# ESP32S31_RADIO register map
Vendor: Espressif; Series: ESP32-S31; File version: 3.52
Registers are 32-bit, read-write, no defined reset value unless marked. A register's access mark holds for its fields unless they carry their own. Offsets are from the block's base; [hi:lo] are bit positions; {n}, {i} and the like mark numbered series.

## BT_V3_2_BASEBAND — Bluetooth baseband control and status words recovered from complete, named bt_bb_v2.o accessors in the ESP32-S31 vendor library. Field geometry and argument-to-field transforms are exact. ARGUMENT_N labels deliberately retain unknown C signature semantics rather than inventing a hardware meaning.
Base 0x20102000
0x00 RX_SETUP_CONTROL_0 — Complete bt_bb_rx_set sets positional bit 0 through a fresh-read RMW. Its independent hardware meaning remains unknown.
  [0] SET_BY_RX_SETUP_BIT_0 — Complete bt_bb_rx_set sets this positional bit. No enable semantic is proven.
0x04 CHANNEL_POWER_CONTROL — The named channel-power set/unset leaves set or clear this aggregate two-bit field through fresh-read RMW operations; individual bit meanings remain unknown.
  [9:8] CHANNEL_POWER_BITS_8_9 — bt_get_channel_pwr_set replaces the field with 3 and bt_get_channel_pwr_unset replaces it with 0.
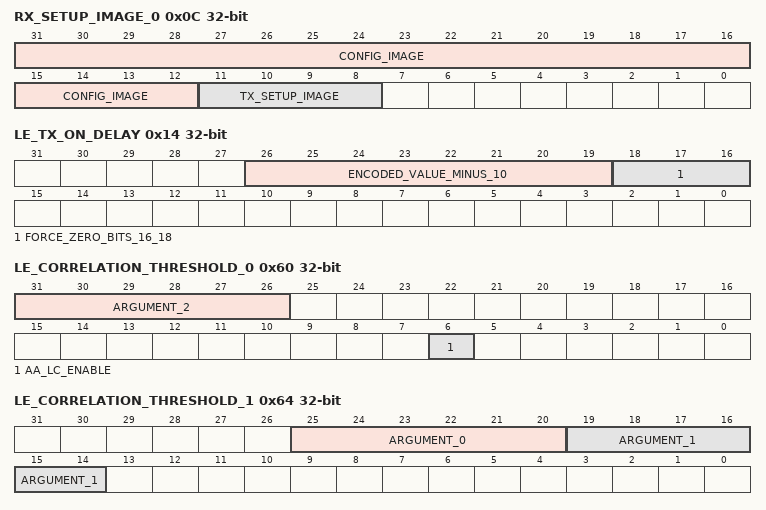
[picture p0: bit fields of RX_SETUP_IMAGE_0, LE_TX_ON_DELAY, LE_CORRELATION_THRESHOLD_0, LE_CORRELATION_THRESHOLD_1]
0x0C RX_SETUP_IMAGE_0 — The bounded TX setup clears bits 8:11; the subsequent RX setup preserves the low 12 bits and replaces bits 31:12 with the finite image 0x0199A.
  [31:12] CONFIG_IMAGE
  [11:8] TX_SETUP_IMAGE — bt_bb_v2_tx_set replaces this positional field with zero.
0x14 LE_TX_ON_DELAY — Bluetooth LE transmit-on delay. The public API exposes the decoded value; the register stores value minus 10.
  [26:19] ENCODED_VALUE_MINUS_10 — bt_bb_set_le_tx_on_delay stores argument 0 minus 10; bt_bb_get_le_tx_on_delay returns this field plus 10.
  [18:16] FORCE_ZERO_BITS_16_18 — bt_bb_set_le_tx_on_delay clears these three low positional bits in the same RMW that writes the encoded delay. Their hardware meaning remains unknown.
0x1C TX_CONFIG_CHECK_VALUE ro — ble_tx_config_check consumes only this high five-bit image in diagnostic arithmetic; its underlying hardware meaning remains unknown.
  [31:27] HIGH_5_UNKNOWN — Exact value produced by shifting the complete register image right by 27.
0x4C RX_SETUP_CONTROL_1 — Complete bt_bb_rx_set sets positional bit 2 through a fresh-read RMW. Its independent hardware meaning remains unknown.
  [2] SET_BY_RX_SETUP_BIT_2 — Complete bt_bb_rx_set sets this positional bit. No enable semantic is proven.
0x60 LE_CORRELATION_THRESHOLD_0 — Bluetooth LE correlation-threshold control. Only independently observed fields are assigned.
  [31:26] ARGUMENT_2 — bt_bb_set_corr_thresh_le copies its six-bit argument 2 image into this field.
  [6] AA_LC_ENABLE — bt_bb_corr_thresh_aa_lc_en replaces this bit with the Boolean image of argument 0.
0x64 LE_CORRELATION_THRESHOLD_1 — Two independently replaced six-bit Bluetooth LE correlation-threshold images.
  [25:20] ARGUMENT_0 — bt_bb_set_corr_thresh_le copies its six-bit argument 0 image into this field.
  [19:14] ARGUMENT_1 — bt_bb_set_corr_thresh_le copies its six-bit argument 1 image into this field.
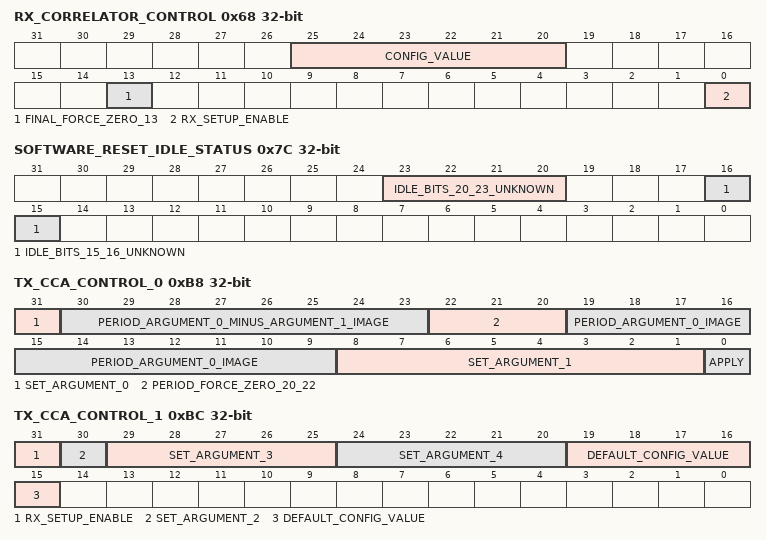
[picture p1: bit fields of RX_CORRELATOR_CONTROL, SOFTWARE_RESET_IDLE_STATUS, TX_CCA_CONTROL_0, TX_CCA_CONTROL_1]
0x68 RX_CORRELATOR_CONTROL — Bluetooth receive-correlator control. The finite initializer sets a low control bit and later replaces the independently observed six-bit configuration value.
  [25:20] CONFIG_VALUE — bt_bb_rx_correlator_set replaces this field with the finite value 8.
  [13] FINAL_FORCE_ZERO_13 — bt_bb_v2_rx_set clears this independently observed control bit after the receive leaf sequence.
  [0] RX_SETUP_ENABLE — bt_agc_restart_set sets this independently observed low control bit.
0x7C SOFTWARE_RESET_IDLE_STATUS ro — bbmac_idle_for_swrst requires both independently tested status fields to be zero before reporting idle.
  [23:20] IDLE_BITS_20_23_UNKNOWN — The reset-idle predicate fails when this exact four-bit field is nonzero.
  [16:15] IDLE_BITS_15_16_UNKNOWN — The reset-idle predicate fails when this exact two-bit field is nonzero.
0xB0 CURRENT_RX_INFO ro — Complete current Bluetooth receive-information image returned by bt_bb_get_cur_rx_info. Inner status encoding remains unknown.
  [31:0] IMAGE
0xB8 TX_CCA_CONTROL_0 — First Bluetooth transmit-CCA control word, including the period transform and fields supplied by bt_bb_tx_cca_set.
  [31] SET_ARGUMENT_0 — Boolean image of bt_bb_tx_cca_set argument 0.
  [30:23] PERIOD_ARGUMENT_0_MINUS_ARGUMENT_1_IMAGE — Eight-bit image produced by bt_bb_tx_cca_period from arguments 0 and 1 using the exact vendor arithmetic.
  [22:20] PERIOD_FORCE_ZERO_20_22 — bt_bb_tx_cca_period explicitly clears bits 20:22 in the same fresh-read update that replaces bits 23:30.
  [19:9] PERIOD_ARGUMENT_0_IMAGE — Eleven-bit image produced by bt_bb_tx_cca_period from argument 0 using the exact vendor arithmetic.
  [8:1] SET_ARGUMENT_1 — Eight-bit image of bt_bb_tx_cca_set argument 1.
  [0] APPLY — bt_bb_tx_cca_set unconditionally sets this bit after updating argument fields. No wider trigger semantics are claimed.
0xBC TX_CCA_CONTROL_1 — Second Bluetooth transmit-CCA control word. Argument meaning is not available from the stripped C signature.
  [31] RX_SETUP_ENABLE — bt_bb_rx_set sets this independently observed bit.
  [30] SET_ARGUMENT_2
  [29:25] SET_ARGUMENT_3
  [24:20] SET_ARGUMENT_4
  [19:15] DEFAULT_CONFIG_VALUE — bt_bb_cca_config replaces this field with the finite value 5.
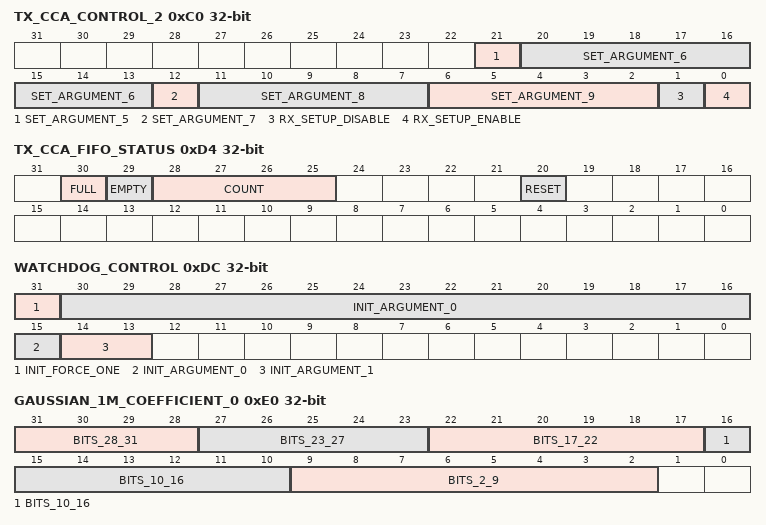
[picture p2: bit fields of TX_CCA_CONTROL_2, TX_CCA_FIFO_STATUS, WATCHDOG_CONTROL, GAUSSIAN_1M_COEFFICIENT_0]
0xC0 TX_CCA_CONTROL_2 — Third Bluetooth transmit-CCA control word. Argument meaning is not available from the stripped C signature.
  [21] SET_ARGUMENT_5
  [20:13] SET_ARGUMENT_6
  [12] SET_ARGUMENT_7
  [11:7] SET_ARGUMENT_8
  [6:2] SET_ARGUMENT_9
  [1] RX_SETUP_DISABLE — bt_bb_rx_set clears this bit before setting RX_SETUP_ENABLE.
  [0] RX_SETUP_ENABLE — bt_bb_rx_set sets this bit after clearing RX_SETUP_DISABLE.
0xD4 TX_CCA_FIFO_STATUS — Bluetooth transmit-CCA FIFO reset and status word recovered from five dedicated accessors.
  [30] FULL ro — Boolean returned by bt_bb_tx_cca_fifo_full.
  [29] EMPTY ro — Boolean returned by bt_bb_tx_cca_fifo_empty.
  [28:25] COUNT ro — Four-bit value returned by bt_bb_tx_cca_fifo_count.
  [20] RESET — bt_bb_tx_cca_fifo_reset sets this bit.
0xD8 TX_CCA_FIFO_DATA ro — Complete 32-bit FIFO word returned by bt_bb_tx_cca_fifo_read; inner encoding remains unknown.
  [31:0] IMAGE
0xDC WATCHDOG_CONTROL — Bluetooth baseband watchdog initialization word. Only the exact bt_bb_wdt_init writes are assigned.
  [31] INIT_FORCE_ONE — bt_bb_wdt_init sets this bit before writing both argument fields.
  [30:15] INIT_ARGUMENT_0 — Sixteen-bit image of bt_bb_wdt_init argument 0.
  [14:13] INIT_ARGUMENT_1 — Two-bit image of bt_bb_wdt_init argument 1.
0xE0 GAUSSIAN_1M_COEFFICIENT_0 — First word configured by the complete set_gauss_coeff_1m leaf; names retain positional fields because individual coefficient semantics are unknown.
  [31:28] BITS_28_31 — The leaf replaces this field with 0.
  [27:23] BITS_23_27 — The leaf replaces this field with 0.
  [22:17] BITS_17_22 — The leaf replaces this field with 0.
  [16:10] BITS_10_16 — The leaf replaces this field with 3.
  [9:2] BITS_2_9 — The leaf replaces this field with 0x13.
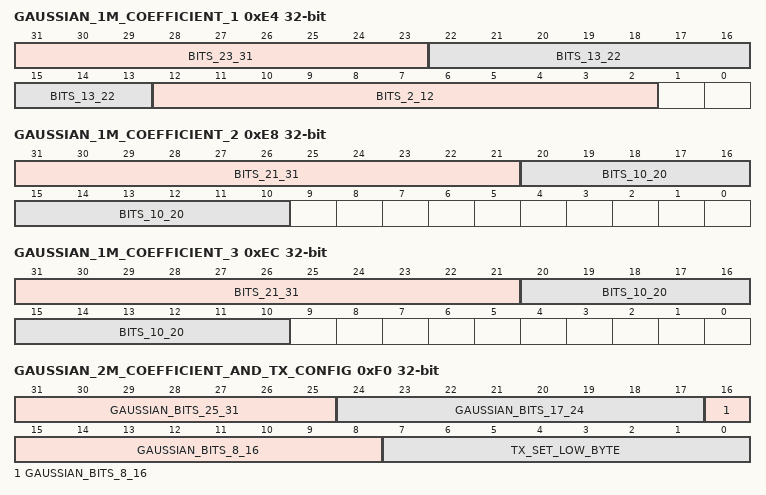
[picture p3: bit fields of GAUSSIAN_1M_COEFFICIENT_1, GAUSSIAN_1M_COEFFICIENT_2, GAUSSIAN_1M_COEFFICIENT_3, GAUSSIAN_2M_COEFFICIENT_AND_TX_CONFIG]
0xE4 GAUSSIAN_1M_COEFFICIENT_1 — Second word configured by the complete set_gauss_coeff_1m leaf.
  [31:23] BITS_23_31 — The leaf replaces this field with 0x5f.
  [22:13] BITS_13_22 — The leaf replaces this field with 0x140.
  [12:2] BITS_2_12 — The leaf replaces this field with 0x2f2.
0xE8 GAUSSIAN_1M_COEFFICIENT_2 — Third word configured by the complete set_gauss_coeff_1m leaf.
  [31:21] BITS_21_31 — The leaf replaces this field with 0x50d.
  [20:10] BITS_10_20 — The leaf replaces this field with 0x6bf.
0xEC GAUSSIAN_1M_COEFFICIENT_3 — Fourth word configured by the complete set_gauss_coeff_1m leaf.
  [31:21] BITS_21_31 — The leaf replaces this field with 0x7a0.
  [20:10] BITS_10_20 — The leaf replaces this field with 0x7e9.
0xF0 GAUSSIAN_2M_COEFFICIENT_AND_TX_CONFIG — The complete 2M Gaussian-coefficient leaf owns bits 31:8 while bt_bb_v2_tx_set independently owns the low-byte image of this same physical word.
  [31:25] GAUSSIAN_BITS_25_31 — set_gauss_coeff_2m replaces this field with 0.
  [24:17] GAUSSIAN_BITS_17_24 — set_gauss_coeff_2m replaces this field with 7.
  [16:8] GAUSSIAN_BITS_8_16 — set_gauss_coeff_2m replaces this field with 0x69.
  [7:0] TX_SET_LOW_BYTE — bt_bb_v2_tx_set replaces this field with 0xf5.
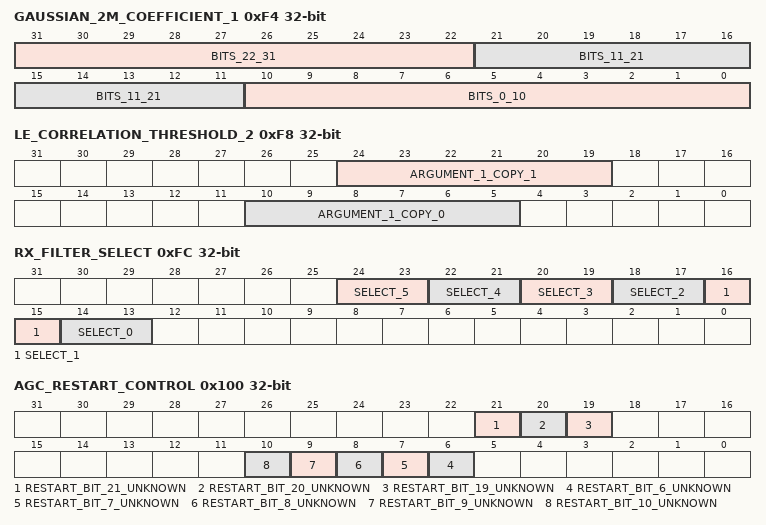
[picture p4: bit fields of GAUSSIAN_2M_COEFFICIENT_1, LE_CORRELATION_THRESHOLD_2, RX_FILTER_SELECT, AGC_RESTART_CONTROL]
0xF4 GAUSSIAN_2M_COEFFICIENT_1 — Second word configured by the complete set_gauss_coeff_2m leaf; its three observed fields cover the complete physical word.
  [31:22] BITS_22_31 — The leaf replaces this field with 0x258.
  [21:11] BITS_11_21 — The leaf replaces this field with 0x5a7.
  [10:0] BITS_0_10 — The leaf replaces this field with 0x78f.
0xF8 LE_CORRELATION_THRESHOLD_2 — Two copies of bt_bb_set_corr_thresh_le argument 1 in independently replaced six-bit fields.
  [24:19] ARGUMENT_1_COPY_1, [10:5] ARGUMENT_1_COPY_0
0xFC RX_FILTER_SELECT — Six independent two-bit Bluetooth receive-filter selections configured by bt_bb_rx_filter_sel. Individual path meanings remain unknown.
  [24:23] SELECT_5 — Configured to the finite value 1.
  [22:21] SELECT_4 — Configured to the finite value 2.
  [20:19] SELECT_3 — Configured to the finite value 0.
  [18:17] SELECT_2 — Configured to the finite value 0.
  [16:15] SELECT_1 — Configured to the finite value 2.
  [14:13] SELECT_0 — Configured to the finite value 2.
0x100 AGC_RESTART_CONTROL — bt_agc_restart_set independently sets eight observed bits through separate fresh-read RMW operations; individual bit meanings remain unknown.
  [21] RESTART_BIT_21_UNKNOWN, [20] RESTART_BIT_20_UNKNOWN, [19] RESTART_BIT_19_UNKNOWN, [n] RESTART_BIT_{n}_UNKNOWN (n=6..10)
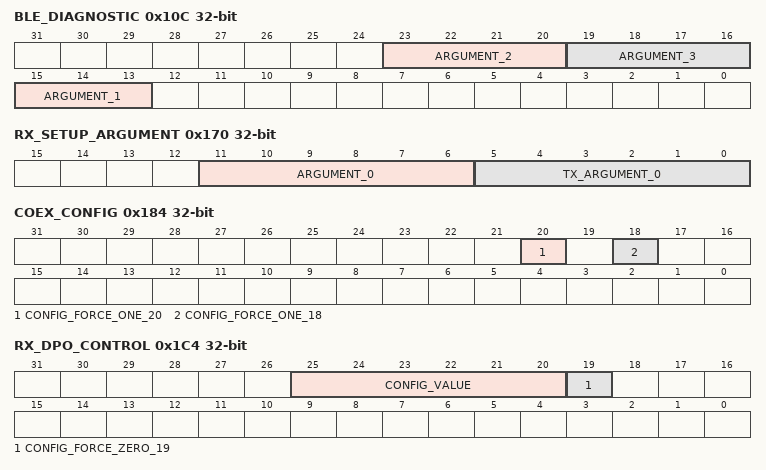
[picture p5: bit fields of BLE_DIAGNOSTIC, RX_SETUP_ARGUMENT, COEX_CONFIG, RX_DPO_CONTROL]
0x10C BLE_DIAGNOSTIC — Three independently replaced Bluetooth diagnostic selector images.
  [23:20] ARGUMENT_2, [19:16] ARGUMENT_3, [15:13] ARGUMENT_1
0x170 RX_SETUP_ARGUMENT — The bounded TX and RX setup leaves update two adjacent positional argument fields through separate fresh reads.
  [11:6] ARGUMENT_0 — bt_bb_rx_set copies its six-bit argument 0 image into this positional field.
  [5:0] TX_ARGUMENT_0 — bt_bb_v2_tx_set copies its six-bit argument 0 image into this positional field.
0x184 COEX_CONFIG — Bluetooth baseband coexistence configuration written by bt_bb_coex_config. Only two finite one-bits are assigned.
  [20] CONFIG_FORCE_ONE_20, [18] CONFIG_FORCE_ONE_18
0x1C4 RX_DPO_CONTROL — Bluetooth receive-DPO configuration written by bt_bb_rx_dpo_set. Inner DPO meaning remains unknown.
  [25:20] CONFIG_VALUE — bt_bb_rx_dpo_set replaces this field with the finite value 2.
  [19] CONFIG_FORCE_ZERO_19
